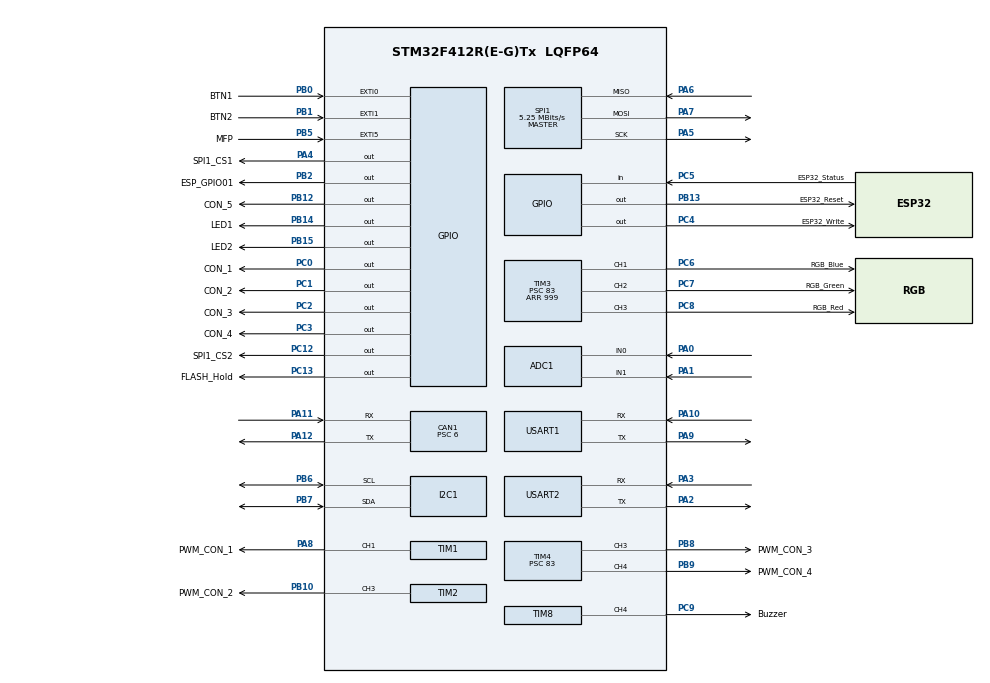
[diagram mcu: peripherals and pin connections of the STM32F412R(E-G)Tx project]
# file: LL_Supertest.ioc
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ADC1.Channel-0\#ChannelRegularConversion=ADC_CHANNEL_0
ADC1.Channel-1\#ChannelRegularConversion=ADC_CHANNEL_1
ADC1.ContinuousConvMode=ENABLE
ADC1.DMAContinuousRequests=ENABLE
ADC1.InjNumberOfConversion=0
ADC1.NbrOfConversion=2
ADC1.NbrOfConversionFlag=1
ADC1.Rank-0\#ChannelRegularConversion=1
ADC1.Rank-1\#ChannelRegularConversion=2
ADC1.SamplingTime-0\#ChannelRegularConversion=ADC_SAMPLETIME_15CYCLES
ADC1.SamplingTime-1\#ChannelRegularConversion=ADC_SAMPLETIME_15CYCLES
ADC1.ScanConvMode=ENABLE
ADC1.master=1
CAN1.BS1=CAN_BS1_11TQ
CAN1.BS2=CAN_BS2_2TQ
CAN1.CalculateBaudRate=500000
CAN1.CalculateTimeBit=2000
CAN1.CalculateTimeQuantum=142.85714285714286
CAN1.NART=ENABLE
CAN1.Prescaler=6
CAN1.SJW=CAN_SJW_1TQ
Dma.ADC1.0.Direction=DMA_PERIPH_TO_MEMORY
Dma.ADC1.0.FIFOMode=DMA_FIFOMODE_DISABLE
Dma.ADC1.0.Instance=DMA2_Stream4
Dma.ADC1.0.MemDataAlignment=DMA_MDATAALIGN_HALFWORD
Dma.ADC1.0.MemInc=DMA_MINC_ENABLE
Dma.ADC1.0.Mode=DMA_CIRCULAR
Dma.ADC1.0.PeriphDataAlignment=DMA_PDATAALIGN_HALFWORD
Dma.ADC1.0.PeriphInc=DMA_PINC_DISABLE
Dma.ADC1.0.Priority=DMA_PRIORITY_LOW
Dma.I2C1_RX.1.Direction=DMA_PERIPH_TO_MEMORY
Dma.I2C1_RX.1.FIFOMode=DMA_FIFOMODE_DISABLE
Dma.I2C1_RX.1.Instance=DMA1_Stream0
Dma.I2C1_RX.1.MemDataAlignment=DMA_MDATAALIGN_BYTE
Dma.I2C1_RX.1.MemInc=DMA_MINC_ENABLE
Dma.I2C1_RX.1.Mode=DMA_NORMAL
Dma.I2C1_RX.1.PeriphDataAlignment=DMA_PDATAALIGN_BYTE
Dma.I2C1_RX.1.PeriphInc=DMA_PINC_DISABLE
Dma.I2C1_RX.1.Priority=DMA_PRIORITY_LOW
Dma.I2C1_TX.2.Direction=DMA_MEMORY_TO_PERIPH
Dma.I2C1_TX.2.FIFOMode=DMA_FIFOMODE_DISABLE
Dma.I2C1_TX.2.Instance=DMA1_Stream1
Dma.I2C1_TX.2.MemDataAlignment=DMA_MDATAALIGN_BYTE
Dma.I2C1_TX.2.MemInc=DMA_MINC_ENABLE
Dma.I2C1_TX.2.Mode=DMA_NORMAL
Dma.I2C1_TX.2.PeriphDataAlignment=DMA_PDATAALIGN_BYTE
Dma.I2C1_TX.2.PeriphInc=DMA_PINC_DISABLE
Dma.I2C1_TX.2.Priority=DMA_PRIORITY_LOW
Dma.Request0=ADC1
Dma.Request1=I2C1_RX
Dma.Request2=I2C1_TX
Dma.Request3=USART1_RX
Dma.Request4=USART1_TX
Dma.Request5=USART2_RX
Dma.Request6=USART2_TX
Dma.Request7=SPI1_RX
Dma.Request8=SPI1_TX
Dma.SPI1_RX.7.Direction=DMA_PERIPH_TO_MEMORY
Dma.SPI1_RX.7.FIFOMode=DMA_FIFOMODE_DISABLE
Dma.SPI1_RX.7.Instance=DMA2_Stream0
Dma.SPI1_RX.7.MemDataAlignment=DMA_MDATAALIGN_BYTE
Dma.SPI1_RX.7.MemInc=DMA_MINC_ENABLE
Dma.SPI1_RX.7.Mode=DMA_NORMAL
Dma.SPI1_RX.7.PeriphDataAlignment=DMA_PDATAALIGN_BYTE
Dma.SPI1_RX.7.PeriphInc=DMA_PINC_DISABLE
Dma.SPI1_RX.7.Priority=DMA_PRIORITY_LOW
Dma.SPI1_TX.8.Direction=DMA_MEMORY_TO_PERIPH
Dma.SPI1_TX.8.FIFOMode=DMA_FIFOMODE_DISABLE
Dma.SPI1_TX.8.Instance=DMA2_Stream3
Dma.SPI1_TX.8.MemDataAlignment=DMA_MDATAALIGN_BYTE
Dma.SPI1_TX.8.MemInc=DMA_MINC_ENABLE
Dma.SPI1_TX.8.Mode=DMA_NORMAL
Dma.SPI1_TX.8.PeriphDataAlignment=DMA_PDATAALIGN_BYTE
Dma.SPI1_TX.8.PeriphInc=DMA_PINC_DISABLE
Dma.SPI1_TX.8.Priority=DMA_PRIORITY_LOW
Dma.USART1_RX.3.Direction=DMA_PERIPH_TO_MEMORY
Dma.USART1_RX.3.FIFOMode=DMA_FIFOMODE_DISABLE
Dma.USART1_RX.3.Instance=DMA2_Stream2
Dma.USART1_RX.3.MemDataAlignment=DMA_MDATAALIGN_BYTE
Dma.USART1_RX.3.MemInc=DMA_MINC_ENABLE
Dma.USART1_RX.3.Mode=DMA_NORMAL
Dma.USART1_RX.3.PeriphDataAlignment=DMA_PDATAALIGN_BYTE
Dma.USART1_RX.3.PeriphInc=DMA_PINC_DISABLE
Dma.USART1_RX.3.Priority=DMA_PRIORITY_LOW
Dma.USART1_TX.4.Direction=DMA_MEMORY_TO_PERIPH
Dma.USART1_TX.4.FIFOMode=DMA_FIFOMODE_DISABLE
Dma.USART1_TX.4.Instance=DMA2_Stream7
Dma.USART1_TX.4.MemDataAlignment=DMA_MDATAALIGN_BYTE
Dma.USART1_TX.4.MemInc=DMA_MINC_ENABLE
Dma.USART1_TX.4.Mode=DMA_NORMAL
Dma.USART1_TX.4.PeriphDataAlignment=DMA_PDATAALIGN_BYTE
Dma.USART1_TX.4.PeriphInc=DMA_PINC_DISABLE
Dma.USART1_TX.4.Priority=DMA_PRIORITY_LOW
Dma.USART2_RX.5.Direction=DMA_PERIPH_TO_MEMORY
Dma.USART2_RX.5.FIFOMode=DMA_FIFOMODE_DISABLE
Dma.USART2_RX.5.Instance=DMA1_Stream5
Dma.USART2_RX.5.MemDataAlignment=DMA_MDATAALIGN_BYTE
Dma.USART2_RX.5.MemInc=DMA_MINC_ENABLE
Dma.USART2_RX.5.Mode=DMA_NORMAL
Dma.USART2_RX.5.PeriphDataAlignment=DMA_PDATAALIGN_BYTE
Dma.USART2_RX.5.PeriphInc=DMA_PINC_DISABLE
Dma.USART2_RX.5.Priority=DMA_PRIORITY_LOW
Dma.USART2_TX.6.Direction=DMA_MEMORY_TO_PERIPH
Dma.USART2_TX.6.FIFOMode=DMA_FIFOMODE_DISABLE
Dma.USART2_TX.6.Instance=DMA1_Stream6
Dma.USART2_TX.6.MemDataAlignment=DMA_MDATAALIGN_BYTE
Dma.USART2_TX.6.MemInc=DMA_MINC_ENABLE
Dma.USART2_TX.6.Mode=DMA_NORMAL
Dma.USART2_TX.6.PeriphDataAlignment=DMA_PDATAALIGN_BYTE
Dma.USART2_TX.6.PeriphInc=DMA_PINC_DISABLE
Dma.USART2_TX.6.Priority=DMA_PRIORITY_LOW
Mcu.Family=STM32F4
Mcu.Name=STM32F412R(E-G)Tx
Mcu.Package=LQFP64
Mcu.UserConstants=ADC_CHANNEL_COUNT,2;ADC_SAMPLES_PER_CHANNEL,1;ADC_BUFFER_SIZE,(ADC_CHANNEL_COUNT * ADC_SAMPLES_PER_CHANNEL);FRAME_LEN_APP,32;FRAME_HEADER_SIZE,5;FRAME_PAYLOAD_SIZE,(FRAME_LEN_APP - FRAME_HEADER_SIZE);UART1_RX_BUFFER_SIZE,128;UART1_RX_FRAME_LEN,FRAME_LEN_APP;UART2_RX_BUFFER_SIZE,128;UART2_RX_FRAME_LEN,FRAME_LEN_APP
NVIC.CAN1_RX0_IRQn=true\:0\:0\:false\:false\:true\:true\:true\:true
NVIC.CAN1_RX1_IRQn=true\:0\:0\:false\:false\:true\:true\:true\:true
NVIC.CAN1_SCE_IRQn=true\:0\:0\:false\:false\:true\:true\:true\:true
NVIC.CAN1_TX_IRQn=true\:0\:0\:false\:false\:true\:true\:true\:true
NVIC.DMA1_Stream0_IRQn=true\:0\:0\:false\:false\:true\:false\:true\:true
NVIC.DMA1_Stream1_IRQn=true\:0\:0\:false\:false\:true\:false\:true\:true
NVIC.DMA1_Stream5_IRQn=true\:0\:0\:false\:false\:true\:false\:true\:true
NVIC.DMA1_Stream6_IRQn=true\:0\:0\:false\:false\:true\:false\:true\:true
NVIC.DMA2_Stream0_IRQn=true\:0\:0\:false\:false\:true\:false\:true\:true
NVIC.DMA2_Stream2_IRQn=true\:0\:0\:false\:false\:true\:false\:true\:true
NVIC.DMA2_Stream3_IRQn=true\:0\:0\:false\:false\:true\:false\:true\:true
NVIC.DMA2_Stream4_IRQn=true\:0\:0\:false\:false\:true\:false\:true\:true
NVIC.DMA2_Stream7_IRQn=true\:0\:0\:false\:false\:true\:false\:true\:true
NVIC.I2C1_ER_IRQn=true\:0\:0\:false\:false\:true\:true\:true\:true
NVIC.I2C1_EV_IRQn=true\:0\:0\:false\:false\:true\:true\:true\:true
NVIC.PriorityGroup=NVIC_PRIORITYGROUP_4
NVIC.SPI1_IRQn=true\:0\:0\:false\:false\:true\:true\:true\:true
NVIC.TIM8_UP_TIM13_IRQn=true\:0\:0\:false\:false\:true\:true\:true\:true
NVIC.USART1_IRQn=true\:0\:0\:false\:false\:true\:false\:true\:true
NVIC.USART2_IRQn=true\:0\:0\:false\:false\:true\:false\:true\:true
PA0.Signal=ADCx_IN0
PA1.Signal=ADCx_IN1
PA10.Mode=Asynchronous
PA10.Signal=USART1_RX
PA11.Mode=CAN_Activate
PA11.Signal=CAN1_RX
PA12.Mode=CAN_Activate
PA12.Signal=CAN1_TX
PA13.Mode=JTAG_4_pins
PA13.Signal=SYS_JTMS-SWDIO
PA14.Mode=JTAG_4_pins
PA14.Signal=SYS_JTCK-SWCLK
PA15.Mode=JTAG_4_pins
PA15.Signal=SYS_JTDI
PA2.Mode=Asynchronous
PA2.Signal=USART2_TX
PA3.Mode=Asynchronous
PA3.Signal=USART2_RX
PA4.GPIO_Label=SPI1_CS1
PA4.Signal=GPIO_Output
PA5.Mode=Full_Duplex_Master
PA5.Signal=SPI1_SCK
PA6.Mode=Full_Duplex_Master
PA6.Signal=SPI1_MISO
PA7.Mode=Full_Duplex_Master
PA7.Signal=SPI1_MOSI
PA8.GPIO_Label=PWM_CON_1
PA8.Signal=S_TIM1_CH1
PA9.Mode=Asynchronous
PA9.Signal=USART1_TX
PB0.GPIO_Label=BTN1
PB0.GPIO_ModeDefaultEXTI=GPIO_MODE_IT_FALLING
PB0.GPIO_PuPd=GPIO_PULLUP
PB0.Signal=GPXTI0
PB1.GPIO_Label=BTN2
PB1.GPIO_ModeDefaultEXTI=GPIO_MODE_IT_FALLING
PB1.GPIO_PuPd=GPIO_PULLUP
PB1.Signal=GPXTI1
PB10.GPIO_Label=PWM_CON_2
PB10.Signal=S_TIM2_CH3
PB12.GPIO_Label=CON_5
PB12.Signal=GPIO_Output
PB13.GPIO_Label=ESP32_Reset
PB13.Signal=GPIO_Output
PB14.GPIO_Label=LED1
PB14.Signal=GPIO_Output
PB15.GPIO_Label=LED2
PB15.Signal=GPIO_Output
PB2.GPIO_Label=ESP_GPIO01
PB2.Signal=GPIO_Output
PB3.Mode=JTAG_4_pins
PB3.Signal=SYS_JTDO-SWO
PB5.GPIO_Label=MFP
PB5.GPIO_ModeDefaultEXTI=GPIO_MODE_IT_FALLING
PB5.Signal=GPXTI5
PB6.Mode=I2C
PB6.Signal=I2C1_SCL
PB7.Mode=I2C
PB7.Signal=I2C1_SDA
PB8.GPIO_Label=PWM_CON_3
PB8.Signal=S_TIM4_CH3
PB9.GPIO_Label=PWM_CON_4
PB9.Signal=S_TIM4_CH4
PC0.GPIO_Label=CON_1
PC0.Signal=GPIO_Output
PC1.GPIO_Label=CON_2
PC1.Signal=GPIO_Output
PC12.GPIO_Label=SPI1_CS2
PC12.Signal=GPIO_Output
PC13.GPIO_Label=FLASH_Hold
PC13.Signal=GPIO_Output
PC14-OSC32_IN.Mode=LSE-External-Oscillator
PC14-OSC32_IN.Signal=RCC_OSC32_IN
PC15-OSC32_OUT.Mode=LSE-External-Oscillator
PC15-OSC32_OUT.Signal=RCC_OSC32_OUT
PC2.GPIO_Label=CON_3
PC2.Signal=GPIO_Output
PC3.GPIO_Label=CON_4
PC3.Signal=GPIO_Output
PC4.GPIO_Label=ESP32_Write
PC4.Signal=GPIO_Output
PC5.GPIO_Label=ESP32_Status
PC5.Signal=GPIO_Input
PC6.GPIO_Label=RGB_Blue
PC6.Signal=S_TIM3_CH1
PC7.GPIO_Label=RGB_Green
PC7.Signal=S_TIM3_CH2
PC8.GPIO_Label=RGB_Red
PC8.Signal=S_TIM3_CH3
PC9.GPIO_Label=Buzzer
PC9.Signal=S_TIM8_CH4
PH0\ -\ OSC_IN.Mode=HSE-External-Clock-Source
PH0\ -\ OSC_IN.Signal=RCC_OSC_IN
PH1\ -\ OSC_OUT.Mode=HSE-External-Clock-Source
PH1\ -\ OSC_OUT.Signal=RCC_OSC_OUT
ProjectManager.HeapSize=0x200
ProjectManager.StackSize=0x400
ProjectManager.TargetToolchain=CMake
RCC.AHBFreq_Value=84000000
RCC.APB1CLKDivider=RCC_HCLK_DIV2
RCC.APB1Freq_Value=42000000
RCC.APB1TimFreq_Value=84000000
RCC.APB2Freq_Value=84000000
RCC.APB2TimFreq_Value=84000000
RCC.CortexFreq_Value=84000000
RCC.HCLKFreq_Value=84000000
RCC.PLLM=8
RCC.PLLN=84
RCC.SYSCLKFreq_VALUE=84000000
RCC.SYSCLKSource=RCC_SYSCLKSOURCE_PLLCLK
RCC.USBFreq_Value=84000000
RCC.VCOOutputFreq_Value=168000000
SH.ADCx_IN0.0=ADC1_IN0,IN0
SH.ADCx_IN1.0=ADC1_IN1,IN1
SH.S_TIM1_CH1.0=TIM1_CH1,PWM Generation1 CH1
SH.S_TIM2_CH3.0=TIM2_CH3,PWM Generation3 CH3
SH.S_TIM3_CH1.0=TIM3_CH1,PWM Generation1 CH1
SH.S_TIM3_CH2.0=TIM3_CH2,PWM Generation2 CH2
SH.S_TIM3_CH3.0=TIM3_CH3,PWM Generation3 CH3
SH.S_TIM4_CH3.0=TIM4_CH3,PWM Generation3 CH3
SH.S_TIM4_CH4.0=TIM4_CH4,PWM Generation4 CH4
SH.S_TIM8_CH4.0=TIM8_CH4,PWM Generation4 CH4
SPI1.BaudRatePrescaler=SPI_BAUDRATEPRESCALER_16
SPI1.CRCCalculation=SPI_CRCCALCULATION_DISABLE
SPI1.CalculateBaudRate=5.25 MBits/s
SPI1.Direction=SPI_DIRECTION_2LINES
SPI1.Mode=SPI_MODE_MASTER
SPI1.VirtualType=VM_MASTER
TIM1.Channel-PWM\ Generation1\ CH1=TIM_CHANNEL_1
TIM1.Period=999
TIM1.Prescaler=83
TIM13.Channel=TIM_CHANNEL_1
TIM13.Period=999
TIM13.Prescaler=83
TIM13.Pulse=500
TIM2.Channel-PWM\ Generation3\ CH3=TIM_CHANNEL_3
TIM2.Period=999
TIM2.Prescaler=83
TIM3.Channel-PWM\ Generation1\ CH1=TIM_CHANNEL_1
TIM3.Channel-PWM\ Generation2\ CH2=TIM_CHANNEL_2
TIM3.Channel-PWM\ Generation3\ CH3=TIM_CHANNEL_3
TIM3.Period=999
TIM3.Prescaler=83
TIM4.Channel-PWM\ Generation3\ CH3=TIM_CHANNEL_3
TIM4.Channel-PWM\ Generation4\ CH4=TIM_CHANNEL_4
TIM4.Period=999
TIM4.Prescaler=83
TIM8.Channel-PWM\ Generation4\ CH4=TIM_CHANNEL_4
TIM8.Period=999
TIM8.Prescaler=83
USART1.VirtualMode=VM_ASYNC
USART2.VirtualMode=VM_ASYNC
VP_CRC_VS_CRC.Mode=CRC_Activate
VP_RTC_VS_RTC_Activate.Mode=RTC_Enabled
VP_RTC_VS_RTC_Calendar.Mode=RTC_Calendar
VP_TIM13_VS_ClockSourceINT.Mode=Enable_Timer
VP_TIM13_VS_no_output1.Mode=Output Compare1 No Output
board=custom

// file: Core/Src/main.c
#include "main.h"
#include "app_flags.h"
#include "support.h"
#include "uart_protocol.h"
#include "uart.h"
#include "spi.h"
#include "bme280.h"
#include "sht40.h"
#include "lcd.h"
#include "rtc.h"
#include "can.h"
#include "can_protocol.h"

CAN_HandleTypeDef hcan1;

void SystemClock_Config(void);
static void MX_GPIO_Init(void);
static void MX_DMA_Init(void);
static void MX_ADC1_Init(void);
static void MX_CAN1_Init(void);
static void MX_I2C1_Init(void);
static void MX_TIM1_Init(void);
static void MX_TIM2_Init(void);
static void MX_TIM3_Init(void);
static void MX_TIM4_Init(void);
static void MX_TIM8_Init(void);
static void MX_TIM13_Init(void);
static void MX_USART1_UART_Init(void);
static void MX_USART2_UART_Init(void);
static void MX_SPI1_Init(void);
static void MX_CRC_Init(void);
static void MX_RTC_Init(void);

int main(void)
{

  /* MCU Configuration--------------------------------------------------------*/

  /* Reset of all peripherals, Initializes the Flash interface and the Systick. */
  __disable_irq();
  SCB->VTOR = 0x08008000U;
  __DSB(); __ISB();

  HAL_Init();

  /* Configure the system clock */
  SystemClock_Config();

  /* Initialize all configured peripherals */
  MX_GPIO_Init();
  MX_DMA_Init();
  MX_ADC1_Init();
  MX_CAN1_Init();
  MX_I2C1_Init();
  MX_TIM1_Init();
  MX_TIM2_Init();
  MX_TIM3_Init();
  MX_TIM4_Init();
  MX_TIM8_Init();
  MX_TIM13_Init();
  MX_USART1_UART_Init();
  MX_USART2_UART_Init();
  MX_SPI1_Init();
  MX_CRC_Init();
  MX_RTC_Init();

  dma1_uart2_rx_config(uart2_rx_buf, UART2_RX_BUFFER_SIZE);
  dma2_uart1_rx_config(uart1_rx_buf, UART1_RX_BUFFER_SIZE);

  __enable_irq();

  bme280_init();

  lcd_init();
  lcd_set_cursor(0, 0);
  lcd_send_string("Initializing...");

  if (can_start() != 0)
  {
      Error_Handler();
  }

  /* Infinite loop */
  /* USER CODE BEGIN WHILE */

  while (1)
  {

    uart2_process_rx();
    uart1_process_rx();

    if (btn1_flag)
    {
      btn1_flag = 0;
      LL_GPIO_TogglePin(LED1_GPIO_Port, LED1_Pin);
    }

    if (btn2_flag)
    {
      btn2_flag = 0;
      LL_GPIO_TogglePin(LED2_GPIO_Port, LED2_Pin);
    }

    bme280_task();
    sht40_task();

    if (flag_100ms)
    {
      flag_100ms = 0;
      send_cyclic_frames();
    }

    if (flag_1s)
    {
      flag_1s = 0;
      LL_GPIO_TogglePin(LED1_GPIO_Port, LED1_Pin);

      rtc_get_datetime(&datetime.year, &datetime.month, &datetime.day, &datetime.weekday, &datetime.hours, &datetime.minutes, &datetime.seconds);
    }
    /* USER CODE END WHILE */

  }
}

void SystemClock_Config(void)
{
  LL_FLASH_SetLatency(LL_FLASH_LATENCY_2);
  while(LL_FLASH_GetLatency()!= LL_FLASH_LATENCY_2)
  {
  }
  LL_PWR_SetRegulVoltageScaling(LL_PWR_REGU_VOLTAGE_SCALE1);
  LL_RCC_HSI_SetCalibTrimming(16);
  LL_RCC_HSI_Enable();

   /* Wait till HSI is ready */
  while(LL_RCC_HSI_IsReady() != 1)
  {

  }
  LL_RCC_LSI_Enable();

   /* Wait till LSI is ready */
  while(LL_RCC_LSI_IsReady() != 1)
  {

  }
  LL_PWR_EnableBkUpAccess();
  LL_RCC_PLL_ConfigDomain_SYS(LL_RCC_PLLSOURCE_HSI, LL_RCC_PLLM_DIV_8, 84, LL_RCC_PLLP_DIV_2);
  LL_RCC_PLL_Enable();

   /* Wait till PLL is ready */
  while(LL_RCC_PLL_IsReady() != 1)
  {

  }
  while (LL_PWR_IsActiveFlag_VOS() == 0)
  {
  }
  LL_RCC_SetAHBPrescaler(LL_RCC_SYSCLK_DIV_1);
  LL_RCC_SetAPB1Prescaler(LL_RCC_APB1_DIV_2);
  LL_RCC_SetAPB2Prescaler(LL_RCC_APB2_DIV_1);
  LL_RCC_SetSysClkSource(LL_RCC_SYS_CLKSOURCE_PLL);

   /* Wait till System clock is ready */
  while(LL_RCC_GetSysClkSource() != LL_RCC_SYS_CLKSOURCE_STATUS_PLL)
  {

  }
  LL_SetSystemCoreClock(84000000);

   /* Update the time base */
  if (HAL_InitTick (TICK_INT_PRIORITY) != HAL_OK)
  {
    Error_Handler();
  }
  LL_RCC_SetTIMPrescaler(LL_RCC_TIM_PRESCALER_TWICE);
}

static void MX_ADC1_Init(void)
{

  LL_ADC_InitTypeDef ADC_InitStruct = {0};
  LL_ADC_REG_InitTypeDef ADC_REG_InitStruct = {0};
  LL_ADC_CommonInitTypeDef ADC_CommonInitStruct = {0};

  LL_GPIO_InitTypeDef GPIO_InitStruct = {0};

  /* Peripheral clock enable */
  LL_APB2_GRP1_EnableClock(LL_APB2_GRP1_PERIPH_ADC1);

  LL_AHB1_GRP1_EnableClock(LL_AHB1_GRP1_PERIPH_GPIOA);
  /**ADC1 GPIO Configuration
  PA0   ------> ADC1_IN0
  PA1   ------> ADC1_IN1
  */
  GPIO_InitStruct.Pin = LL_GPIO_PIN_0|LL_GPIO_PIN_1;
  GPIO_InitStruct.Mode = LL_GPIO_MODE_ANALOG;
  GPIO_InitStruct.Pull = LL_GPIO_PULL_NO;
  LL_GPIO_Init(GPIOA, &GPIO_InitStruct);

  /* ADC1 DMA Init */

  /* ADC1 Init */
  LL_DMA_SetChannelSelection(DMA2, LL_DMA_STREAM_4, LL_DMA_CHANNEL_0);

  LL_DMA_SetDataTransferDirection(DMA2, LL_DMA_STREAM_4, LL_DMA_DIRECTION_PERIPH_TO_MEMORY);

  LL_DMA_SetStreamPriorityLevel(DMA2, LL_DMA_STREAM_4, LL_DMA_PRIORITY_LOW);

  LL_DMA_SetMode(DMA2, LL_DMA_STREAM_4, LL_DMA_MODE_CIRCULAR);

  LL_DMA_SetPeriphIncMode(DMA2, LL_DMA_STREAM_4, LL_DMA_PERIPH_NOINCREMENT);

  LL_DMA_SetMemoryIncMode(DMA2, LL_DMA_STREAM_4, LL_DMA_MEMORY_INCREMENT);

  LL_DMA_SetPeriphSize(DMA2, LL_DMA_STREAM_4, LL_DMA_PDATAALIGN_HALFWORD);

  LL_DMA_SetMemorySize(DMA2, LL_DMA_STREAM_4, LL_DMA_MDATAALIGN_HALFWORD);

  LL_DMA_DisableFifoMode(DMA2, LL_DMA_STREAM_4);

  /** Common config
  */
  ADC_InitStruct.Resolution = LL_ADC_RESOLUTION_12B;
  ADC_InitStruct.DataAlignment = LL_ADC_DATA_ALIGN_RIGHT;
  ADC_InitStruct.SequencersScanMode = LL_ADC_SEQ_SCAN_ENABLE;
  LL_ADC_Init(ADC1, &ADC_InitStruct);
  ADC_REG_InitStruct.TriggerSource = LL_ADC_REG_TRIG_SOFTWARE;
  ADC_REG_InitStruct.SequencerLength = LL_ADC_REG_SEQ_SCAN_ENABLE_2RANKS;
  ADC_REG_InitStruct.SequencerDiscont = LL_ADC_REG_SEQ_DISCONT_DISABLE;
  ADC_REG_InitStruct.ContinuousMode = LL_ADC_REG_CONV_CONTINUOUS;
  ADC_REG_InitStruct.DMATransfer = LL_ADC_REG_DMA_TRANSFER_UNLIMITED;
  LL_ADC_REG_Init(ADC1, &ADC_REG_InitStruct);
  LL_ADC_REG_SetFlagEndOfConversion(ADC1, LL_ADC_REG_FLAG_EOC_UNITARY_CONV);
  ADC_CommonInitStruct.CommonClock = LL_ADC_CLOCK_SYNC_PCLK_DIV4;
  LL_ADC_CommonInit(__LL_ADC_COMMON_INSTANCE(ADC1), &ADC_CommonInitStruct);

  /** Configure Regular Channel
  */
  LL_ADC_REG_SetSequencerRanks(ADC1, LL_ADC_REG_RANK_1, LL_ADC_CHANNEL_0);
  LL_ADC_SetChannelSamplingTime(ADC1, LL_ADC_CHANNEL_0, LL_ADC_SAMPLINGTIME_15CYCLES);

  /** Configure Regular Channel
  */
  LL_ADC_REG_SetSequencerRanks(ADC1, LL_ADC_REG_RANK_2, LL_ADC_CHANNEL_1);
  LL_ADC_SetChannelSamplingTime(ADC1, LL_ADC_CHANNEL_1, LL_ADC_SAMPLINGTIME_15CYCLES);

  LL_DMA_SetPeriphAddress(DMA2, LL_DMA_STREAM_4, LL_ADC_DMA_GetRegAddr(ADC1, LL_ADC_DMA_REG_REGULAR_DATA));
  LL_DMA_SetMemoryAddress(DMA2, LL_DMA_STREAM_4, (uint32_t)adc_data_buffer);
  LL_DMA_SetDataLength(DMA2, LL_DMA_STREAM_4, ADC_BUFFER_SIZE);
  LL_DMA_EnableIT_TC(DMA2, LL_DMA_STREAM_4);
  LL_DMA_EnableIT_TE(DMA2, LL_DMA_STREAM_4);
  LL_DMA_EnableStream(DMA2, LL_DMA_STREAM_4);
  LL_ADC_Enable(ADC1);
  LL_ADC_REG_StartConversionSWStart(ADC1);
  adc_present = 1;

}

static void MX_CAN1_Init(void)
{
    hcan1.Instance = CAN1;
    hcan1.Init.Prescaler = 6;
    hcan1.Init.Mode = CAN_MODE_NORMAL;
    hcan1.Init.SyncJumpWidth = CAN_SJW_1TQ;
    hcan1.Init.TimeSeg1 = CAN_BS1_11TQ;
    hcan1.Init.TimeSeg2 = CAN_BS2_2TQ;
    hcan1.Init.TimeTriggeredMode = DISABLE;
    hcan1.Init.AutoBusOff = ENABLE;
    hcan1.Init.AutoWakeUp = DISABLE;
    hcan1.Init.AutoRetransmission = DISABLE;
    hcan1.Init.ReceiveFifoLocked = DISABLE;
    hcan1.Init.TransmitFifoPriority = ENABLE;

    if (HAL_CAN_Init(&hcan1) != HAL_OK)
    {
        Error_Handler();
    }
}

static void MX_CRC_Init(void)
{

  /* Peripheral clock enable */
  LL_AHB1_GRP1_EnableClock(LL_AHB1_GRP1_PERIPH_CRC);

}

static void MX_I2C1_Init(void)
{

  LL_I2C_InitTypeDef I2C_InitStruct = {0};

  LL_GPIO_InitTypeDef GPIO_InitStruct = {0};

  LL_AHB1_GRP1_EnableClock(LL_AHB1_GRP1_PERIPH_GPIOB);
  /**I2C1 GPIO Configuration
  PB6   ------> I2C1_SCL
  PB7   ------> I2C1_SDA
  */
  GPIO_InitStruct.Pin = LL_GPIO_PIN_6|LL_GPIO_PIN_7;
  GPIO_InitStruct.Mode = LL_GPIO_MODE_ALTERNATE;
  GPIO_InitStruct.Speed = LL_GPIO_SPEED_FREQ_VERY_HIGH;
  GPIO_InitStruct.OutputType = LL_GPIO_OUTPUT_OPENDRAIN;
  GPIO_InitStruct.Pull = LL_GPIO_PULL_NO;
  GPIO_InitStruct.Alternate = LL_GPIO_AF_4;
  LL_GPIO_Init(GPIOB, &GPIO_InitStruct);

  /* Peripheral clock enable */
  LL_APB1_GRP1_EnableClock(LL_APB1_GRP1_PERIPH_I2C1);

  /* I2C1 DMA Init */

  /* I2C1_RX Init */
  LL_DMA_SetChannelSelection(DMA1, LL_DMA_STREAM_0, LL_DMA_CHANNEL_1);

  LL_DMA_SetDataTransferDirection(DMA1, LL_DMA_STREAM_0, LL_DMA_DIRECTION_PERIPH_TO_MEMORY);

  LL_DMA_SetStreamPriorityLevel(DMA1, LL_DMA_STREAM_0, LL_DMA_PRIORITY_LOW);

  LL_DMA_SetMode(DMA1, LL_DMA_STREAM_0, LL_DMA_MODE_NORMAL);

  LL_DMA_SetPeriphIncMode(DMA1, LL_DMA_STREAM_0, LL_DMA_PERIPH_NOINCREMENT);

  LL_DMA_SetMemoryIncMode(DMA1, LL_DMA_STREAM_0, LL_DMA_MEMORY_INCREMENT);

  LL_DMA_SetPeriphSize(DMA1, LL_DMA_STREAM_0, LL_DMA_PDATAALIGN_BYTE);

  LL_DMA_SetMemorySize(DMA1, LL_DMA_STREAM_0, LL_DMA_MDATAALIGN_BYTE);

  LL_DMA_DisableFifoMode(DMA1, LL_DMA_STREAM_0);

  /* I2C1_TX Init */
  LL_DMA_SetChannelSelection(DMA1, LL_DMA_STREAM_1, LL_DMA_CHANNEL_0);

  LL_DMA_SetDataTransferDirection(DMA1, LL_DMA_STREAM_1, LL_DMA_DIRECTION_MEMORY_TO_PERIPH);

  LL_DMA_SetStreamPriorityLevel(DMA1, LL_DMA_STREAM_1, LL_DMA_PRIORITY_LOW);

  LL_DMA_SetMode(DMA1, LL_DMA_STREAM_1, LL_DMA_MODE_NORMAL);

  LL_DMA_SetPeriphIncMode(DMA1, LL_DMA_STREAM_1, LL_DMA_PERIPH_NOINCREMENT);

  LL_DMA_SetMemoryIncMode(DMA1, LL_DMA_STREAM_1, LL_DMA_MEMORY_INCREMENT);

  LL_DMA_SetPeriphSize(DMA1, LL_DMA_STREAM_1, LL_DMA_PDATAALIGN_BYTE);

  LL_DMA_SetMemorySize(DMA1, LL_DMA_STREAM_1, LL_DMA_MDATAALIGN_BYTE);

  LL_DMA_DisableFifoMode(DMA1, LL_DMA_STREAM_1);

  /** I2C Initialization
  */
  LL_I2C_DisableOwnAddress2(I2C1);
  LL_I2C_DisableGeneralCall(I2C1);
  LL_I2C_EnableClockStretching(I2C1);
  I2C_InitStruct.PeripheralMode = LL_I2C_MODE_I2C;
  I2C_InitStruct.ClockSpeed = 100000;
  I2C_InitStruct.DutyCycle = LL_I2C_DUTYCYCLE_2;
  I2C_InitStruct.OwnAddress1 = 0;
  I2C_InitStruct.TypeAcknowledge = LL_I2C_ACK;
  I2C_InitStruct.OwnAddrSize = LL_I2C_OWNADDRESS1_7BIT;
  LL_I2C_Init(I2C1, &I2C_InitStruct);
  LL_I2C_SetOwnAddress2(I2C1, 0);
  LL_I2C_EnableDMAReq_RX(I2C1);
  LL_I2C_EnableDMAReq_TX(I2C1);
  LL_I2C_Enable(I2C1);
}

static void MX_RTC_Init(void)
{

  LL_RTC_InitTypeDef RTC_InitStruct = {0};
  LL_RTC_TimeTypeDef RTC_TimeStruct = {0};
  LL_RTC_DateTypeDef RTC_DateStruct = {0};

  if(LL_RCC_GetRTCClockSource() != LL_RCC_RTC_CLKSOURCE_LSI)
  {
    LL_RCC_ForceBackupDomainReset();
    LL_RCC_ReleaseBackupDomainReset();
  LL_RCC_SetRTCClockSource(LL_RCC_RTC_CLKSOURCE_LSI);
  }

  /* Peripheral clock enable */
  LL_RCC_EnableRTC();

  /** Initialize RTC and set the Time and Date
  */
  RTC_InitStruct.HourFormat = LL_RTC_HOURFORMAT_24HOUR;
  RTC_InitStruct.AsynchPrescaler = 127;
  RTC_InitStruct.SynchPrescaler = 255;
  LL_RTC_Init(RTC, &RTC_InitStruct);
  LL_RTC_SetAsynchPrescaler(RTC, 127);
  LL_RTC_SetSynchPrescaler(RTC, 255);

  /** Initialize RTC and set the Time and Date
  */
  if(LL_RTC_BAK_GetRegister(RTC, LL_RTC_BKP_DR0) != 0x32F2){

  RTC_TimeStruct.Hours = 0;
  RTC_TimeStruct.Minutes = 0;
  RTC_TimeStruct.Seconds = 0;
  LL_RTC_TIME_Init(RTC, LL_RTC_FORMAT_BCD, &RTC_TimeStruct);
  RTC_DateStruct.WeekDay = LL_RTC_WEEKDAY_MONDAY;
  RTC_DateStruct.Month = LL_RTC_MONTH_JANUARY;
  RTC_DateStruct.Day = 0x1;
  RTC_DateStruct.Year = 0;
  LL_RTC_DATE_Init(RTC, LL_RTC_FORMAT_BCD, &RTC_DateStruct);
    LL_RTC_BAK_SetRegister(RTC,LL_RTC_BKP_DR0,0x32F2);
  }

}

static void MX_SPI1_Init(void)
{
  LL_SPI_InitTypeDef SPI_InitStruct = {0};

  LL_GPIO_InitTypeDef GPIO_InitStruct = {0};

  LL_APB2_GRP1_EnableClock(LL_APB2_GRP1_PERIPH_SPI1);

  LL_AHB1_GRP1_EnableClock(LL_AHB1_GRP1_PERIPH_GPIOA);

  GPIO_InitStruct.Pin = LL_GPIO_PIN_5|LL_GPIO_PIN_6|LL_GPIO_PIN_7;
  GPIO_InitStruct.Mode = LL_GPIO_MODE_ALTERNATE;
  GPIO_InitStruct.Speed = LL_GPIO_SPEED_FREQ_VERY_HIGH;
  GPIO_InitStruct.OutputType = LL_GPIO_OUTPUT_PUSHPULL;
  GPIO_InitStruct.Pull = LL_GPIO_PULL_NO;
  GPIO_InitStruct.Alternate = LL_GPIO_AF_5;
  LL_GPIO_Init(GPIOA, &GPIO_InitStruct);

  /* SPI1 DMA Init */

  /* SPI1_RX Init */
  LL_DMA_SetChannelSelection(DMA2, LL_DMA_STREAM_0, LL_DMA_CHANNEL_3);

  LL_DMA_SetDataTransferDirection(DMA2, LL_DMA_STREAM_0, LL_DMA_DIRECTION_PERIPH_TO_MEMORY);

  LL_DMA_SetStreamPriorityLevel(DMA2, LL_DMA_STREAM_0, LL_DMA_PRIORITY_LOW);

  LL_DMA_SetMode(DMA2, LL_DMA_STREAM_0, LL_DMA_MODE_NORMAL);

  LL_DMA_SetPeriphIncMode(DMA2, LL_DMA_STREAM_0, LL_DMA_PERIPH_NOINCREMENT);

  LL_DMA_SetMemoryIncMode(DMA2, LL_DMA_STREAM_0, LL_DMA_MEMORY_INCREMENT);

  LL_DMA_SetPeriphSize(DMA2, LL_DMA_STREAM_0, LL_DMA_PDATAALIGN_BYTE);

  LL_DMA_SetMemorySize(DMA2, LL_DMA_STREAM_0, LL_DMA_MDATAALIGN_BYTE);

  LL_DMA_DisableFifoMode(DMA2, LL_DMA_STREAM_0);

  /* SPI1_TX Init */
  LL_DMA_SetChannelSelection(DMA2, LL_DMA_STREAM_3, LL_DMA_CHANNEL_3);

  LL_DMA_SetDataTransferDirection(DMA2, LL_DMA_STREAM_3, LL_DMA_DIRECTION_MEMORY_TO_PERIPH);

  LL_DMA_SetStreamPriorityLevel(DMA2, LL_DMA_STREAM_3, LL_DMA_PRIORITY_LOW);

  LL_DMA_SetMode(DMA2, LL_DMA_STREAM_3, LL_DMA_MODE_NORMAL);

  LL_DMA_SetPeriphIncMode(DMA2, LL_DMA_STREAM_3, LL_DMA_PERIPH_NOINCREMENT);

  LL_DMA_SetMemoryIncMode(DMA2, LL_DMA_STREAM_3, LL_DMA_MEMORY_INCREMENT);

  LL_DMA_SetPeriphSize(DMA2, LL_DMA_STREAM_3, LL_DMA_PDATAALIGN_BYTE);

  LL_DMA_SetMemorySize(DMA2, LL_DMA_STREAM_3, LL_DMA_MDATAALIGN_BYTE);

  LL_DMA_DisableFifoMode(DMA2, LL_DMA_STREAM_3);

  /* SPI1 parameter configuration*/
  SPI_InitStruct.TransferDirection = LL_SPI_FULL_DUPLEX;
  SPI_InitStruct.Mode = LL_SPI_MODE_MASTER;
  SPI_InitStruct.DataWidth = LL_SPI_DATAWIDTH_8BIT;
  SPI_InitStruct.ClockPolarity = LL_SPI_POLARITY_LOW;
  SPI_InitStruct.ClockPhase = LL_SPI_PHASE_1EDGE;
  SPI_InitStruct.NSS = LL_SPI_NSS_SOFT;
  SPI_InitStruct.BaudRate = LL_SPI_BAUDRATEPRESCALER_DIV16;
  SPI_InitStruct.BitOrder = LL_SPI_MSB_FIRST;
  SPI_InitStruct.CRCCalculation = LL_SPI_CRCCALCULATION_DISABLE;
  SPI_InitStruct.CRCPoly = 10;
  LL_SPI_Init(SPI1, &SPI_InitStruct);
  LL_SPI_SetStandard(SPI1, LL_SPI_PROTOCOL_MOTOROLA);
  LL_SPI_EnableDMAReq_RX(SPI1);
  LL_SPI_EnableDMAReq_TX(SPI1);
  LL_SPI_Enable(SPI1);
}

static void MX_TIM1_Init(void)
{

  LL_TIM_InitTypeDef TIM_InitStruct = {0};
  LL_TIM_OC_InitTypeDef TIM_OC_InitStruct = {0};
  LL_TIM_BDTR_InitTypeDef TIM_BDTRInitStruct = {0};

  LL_GPIO_InitTypeDef GPIO_InitStruct = {0};

  /* Peripheral clock enable */
  LL_APB2_GRP1_EnableClock(LL_APB2_GRP1_PERIPH_TIM1);

  TIM_InitStruct.Prescaler = 83;
  TIM_InitStruct.CounterMode = LL_TIM_COUNTERMODE_UP;
  TIM_InitStruct.Autoreload = 999;
  TIM_InitStruct.ClockDivision = LL_TIM_CLOCKDIVISION_DIV1;
  TIM_InitStruct.RepetitionCounter = 0;
  LL_TIM_Init(TIM1, &TIM_InitStruct);
  LL_TIM_DisableARRPreload(TIM1);
  LL_TIM_OC_EnablePreload(TIM1, LL_TIM_CHANNEL_CH1);
  TIM_OC_InitStruct.OCMode = LL_TIM_OCMODE_PWM1;
  TIM_OC_InitStruct.OCState = LL_TIM_OCSTATE_DISABLE;
  TIM_OC_InitStruct.OCNState = LL_TIM_OCSTATE_DISABLE;
  TIM_OC_InitStruct.CompareValue = 0;
  TIM_OC_InitStruct.OCPolarity = LL_TIM_OCPOLARITY_HIGH;
  TIM_OC_InitStruct.OCNPolarity = LL_TIM_OCPOLARITY_HIGH;
  TIM_OC_InitStruct.OCIdleState = LL_TIM_OCIDLESTATE_LOW;
  TIM_OC_InitStruct.OCNIdleState = LL_TIM_OCIDLESTATE_LOW;
  LL_TIM_OC_Init(TIM1, LL_TIM_CHANNEL_CH1, &TIM_OC_InitStruct);
  LL_TIM_OC_DisableFast(TIM1, LL_TIM_CHANNEL_CH1);
  LL_TIM_SetTriggerOutput(TIM1, LL_TIM_TRGO_RESET);
  LL_TIM_DisableMasterSlaveMode(TIM1);
  TIM_BDTRInitStruct.OSSRState = LL_TIM_OSSR_DISABLE;
  TIM_BDTRInitStruct.OSSIState = LL_TIM_OSSI_DISABLE;
  TIM_BDTRInitStruct.LockLevel = LL_TIM_LOCKLEVEL_OFF;
  TIM_BDTRInitStruct.DeadTime = 0;
  TIM_BDTRInitStruct.BreakState = LL_TIM_BREAK_DISABLE;
  TIM_BDTRInitStruct.BreakPolarity = LL_TIM_BREAK_POLARITY_HIGH;
  TIM_BDTRInitStruct.AutomaticOutput = LL_TIM_AUTOMATICOUTPUT_DISABLE;
  LL_TIM_BDTR_Init(TIM1, &TIM_BDTRInitStruct);
  LL_AHB1_GRP1_EnableClock(LL_AHB1_GRP1_PERIPH_GPIOA);
  /**TIM1 GPIO Configuration
  PA8   ------> TIM1_CH1
  */
  GPIO_InitStruct.Pin = PWM_CON_1_Pin;
  GPIO_InitStruct.Mode = LL_GPIO_MODE_ALTERNATE;
  GPIO_InitStruct.Speed = LL_GPIO_SPEED_FREQ_LOW;
  GPIO_InitStruct.OutputType = LL_GPIO_OUTPUT_PUSHPULL;
  GPIO_InitStruct.Pull = LL_GPIO_PULL_NO;
  GPIO_InitStruct.Alternate = LL_GPIO_AF_1;
  LL_GPIO_Init(PWM_CON_1_GPIO_Port, &GPIO_InitStruct);

  LL_TIM_CC_EnableChannel(TIM1, LL_TIM_CHANNEL_CH1);
  LL_TIM_EnableAllOutputs(TIM1);
  LL_TIM_EnableCounter(TIM1);
}

static void MX_TIM2_Init(void)
{

  LL_TIM_InitTypeDef TIM_InitStruct = {0};
  LL_TIM_OC_InitTypeDef TIM_OC_InitStruct = {0};

  LL_GPIO_InitTypeDef GPIO_InitStruct = {0};

  /* Peripheral clock enable */
  LL_APB1_GRP1_EnableClock(LL_APB1_GRP1_PERIPH_TIM2);

  TIM_InitStruct.Prescaler = 83;
  TIM_InitStruct.CounterMode = LL_TIM_COUNTERMODE_UP;
  TIM_InitStruct.Autoreload = 999;
  TIM_InitStruct.ClockDivision = LL_TIM_CLOCKDIVISION_DIV1;
  LL_TIM_Init(TIM2, &TIM_InitStruct);
  LL_TIM_DisableARRPreload(TIM2);
  LL_TIM_OC_EnablePreload(TIM2, LL_TIM_CHANNEL_CH3);
  TIM_OC_InitStruct.OCMode = LL_TIM_OCMODE_PWM1;
  TIM_OC_InitStruct.OCState = LL_TIM_OCSTATE_DISABLE;
  TIM_OC_InitStruct.OCNState = LL_TIM_OCSTATE_DISABLE;
  TIM_OC_InitStruct.CompareValue = 0;
  TIM_OC_InitStruct.OCPolarity = LL_TIM_OCPOLARITY_HIGH;
  LL_TIM_OC_Init(TIM2, LL_TIM_CHANNEL_CH3, &TIM_OC_InitStruct);
  LL_TIM_OC_DisableFast(TIM2, LL_TIM_CHANNEL_CH3);
  LL_TIM_SetTriggerOutput(TIM2, LL_TIM_TRGO_RESET);
  LL_TIM_DisableMasterSlaveMode(TIM2);
  LL_AHB1_GRP1_EnableClock(LL_AHB1_GRP1_PERIPH_GPIOB);
  /**TIM2 GPIO Configuration
  PB10   ------> TIM2_CH3
  */
  GPIO_InitStruct.Pin = PWM_CON_2_Pin;
  GPIO_InitStruct.Mode = LL_GPIO_MODE_ALTERNATE;
  GPIO_InitStruct.Speed = LL_GPIO_SPEED_FREQ_LOW;
  GPIO_InitStruct.OutputType = LL_GPIO_OUTPUT_PUSHPULL;
  GPIO_InitStruct.Pull = LL_GPIO_PULL_NO;
  GPIO_InitStruct.Alternate = LL_GPIO_AF_1;
  LL_GPIO_Init(PWM_CON_2_GPIO_Port, &GPIO_InitStruct);
  LL_TIM_CC_EnableChannel(TIM2, LL_TIM_CHANNEL_CH3);
  LL_TIM_EnableCounter(TIM2);
}

static void MX_TIM3_Init(void)
{

  LL_TIM_InitTypeDef TIM_InitStruct = {0};
  LL_TIM_OC_InitTypeDef TIM_OC_InitStruct = {0};

  LL_GPIO_InitTypeDef GPIO_InitStruct = {0};

  /* Peripheral clock enable */
  LL_APB1_GRP1_EnableClock(LL_APB1_GRP1_PERIPH_TIM3);

  TIM_InitStruct.Prescaler = 83;
  TIM_InitStruct.CounterMode = LL_TIM_COUNTERMODE_UP;
  TIM_InitStruct.Autoreload = 999;
  TIM_InitStruct.ClockDivision = LL_TIM_CLOCKDIVISION_DIV1;
  LL_TIM_Init(TIM3, &TIM_InitStruct);
  LL_TIM_DisableARRPreload(TIM3);
  LL_TIM_OC_EnablePreload(TIM3, LL_TIM_CHANNEL_CH1);
  TIM_OC_InitStruct.OCMode = LL_TIM_OCMODE_PWM1;
  TIM_OC_InitStruct.OCState = LL_TIM_OCSTATE_DISABLE;
  TIM_OC_InitStruct.OCNState = LL_TIM_OCSTATE_DISABLE;
  TIM_OC_InitStruct.CompareValue = 0;
  TIM_OC_InitStruct.OCPolarity = LL_TIM_OCPOLARITY_HIGH;
  LL_TIM_OC_Init(TIM3, LL_TIM_CHANNEL_CH1, &TIM_OC_InitStruct);
  LL_TIM_OC_DisableFast(TIM3, LL_TIM_CHANNEL_CH1);
  LL_TIM_OC_EnablePreload(TIM3, LL_TIM_CHANNEL_CH2);
  LL_TIM_OC_Init(TIM3, LL_TIM_CHANNEL_CH2, &TIM_OC_InitStruct);
  LL_TIM_OC_DisableFast(TIM3, LL_TIM_CHANNEL_CH2);
  LL_TIM_OC_EnablePreload(TIM3, LL_TIM_CHANNEL_CH3);
  LL_TIM_OC_Init(TIM3, LL_TIM_CHANNEL_CH3, &TIM_OC_InitStruct);
  LL_TIM_OC_DisableFast(TIM3, LL_TIM_CHANNEL_CH3);
  LL_TIM_SetTriggerOutput(TIM3, LL_TIM_TRGO_RESET);
  LL_TIM_DisableMasterSlaveMode(TIM3);
  LL_AHB1_GRP1_EnableClock(LL_AHB1_GRP1_PERIPH_GPIOC);
  /**TIM3 GPIO Configuration
  PC6   ------> TIM3_CH1
  PC7   ------> TIM3_CH2
  PC8   ------> TIM3_CH3
  */
  GPIO_InitStruct.Pin = RGB_Blue_Pin|RGB_Green_Pin|RGB_Red_Pin;
  GPIO_InitStruct.Mode = LL_GPIO_MODE_ALTERNATE;
  GPIO_InitStruct.Speed = LL_GPIO_SPEED_FREQ_LOW;
  GPIO_InitStruct.OutputType = LL_GPIO_OUTPUT_PUSHPULL;
  GPIO_InitStruct.Pull = LL_GPIO_PULL_NO;
  GPIO_InitStruct.Alternate = LL_GPIO_AF_2;
  LL_GPIO_Init(GPIOC, &GPIO_InitStruct);
  LL_TIM_CC_EnableChannel(TIM3, LL_TIM_CHANNEL_CH1);
  LL_TIM_CC_EnableChannel(TIM3, LL_TIM_CHANNEL_CH2);
  LL_TIM_CC_EnableChannel(TIM3, LL_TIM_CHANNEL_CH3);
  LL_TIM_EnableCounter(TIM3);
}

static void MX_TIM4_Init(void)
{

  LL_TIM_InitTypeDef TIM_InitStruct = {0};
  LL_TIM_OC_InitTypeDef TIM_OC_InitStruct = {0};

  LL_GPIO_InitTypeDef GPIO_InitStruct = {0};

  /* Peripheral clock enable */
  LL_APB1_GRP1_EnableClock(LL_APB1_GRP1_PERIPH_TIM4);

  TIM_InitStruct.Prescaler = 83;
  TIM_InitStruct.CounterMode = LL_TIM_COUNTERMODE_UP;
  TIM_InitStruct.Autoreload = 999;
  TIM_InitStruct.ClockDivision = LL_TIM_CLOCKDIVISION_DIV1;
  LL_TIM_Init(TIM4, &TIM_InitStruct);
  LL_TIM_DisableARRPreload(TIM4);
  LL_TIM_OC_EnablePreload(TIM4, LL_TIM_CHANNEL_CH3);
  TIM_OC_InitStruct.OCMode = LL_TIM_OCMODE_PWM1;
  TIM_OC_InitStruct.OCState = LL_TIM_OCSTATE_DISABLE;
  TIM_OC_InitStruct.OCNState = LL_TIM_OCSTATE_DISABLE;
  TIM_OC_InitStruct.CompareValue = 0;
  TIM_OC_InitStruct.OCPolarity = LL_TIM_OCPOLARITY_HIGH;
  LL_TIM_OC_Init(TIM4, LL_TIM_CHANNEL_CH3, &TIM_OC_InitStruct);
  LL_TIM_OC_DisableFast(TIM4, LL_TIM_CHANNEL_CH3);
  LL_TIM_OC_EnablePreload(TIM4, LL_TIM_CHANNEL_CH4);
  LL_TIM_OC_Init(TIM4, LL_TIM_CHANNEL_CH4, &TIM_OC_InitStruct);
  LL_TIM_OC_DisableFast(TIM4, LL_TIM_CHANNEL_CH4);
  LL_TIM_SetTriggerOutput(TIM4, LL_TIM_TRGO_RESET);
  LL_TIM_DisableMasterSlaveMode(TIM4);
  LL_AHB1_GRP1_EnableClock(LL_AHB1_GRP1_PERIPH_GPIOB);
  /**TIM4 GPIO Configuration
  PB8   ------> TIM4_CH3
  PB9   ------> TIM4_CH4
  */
  GPIO_InitStruct.Pin = PWM_CON_3_Pin|PWM_CON_4_Pin;
  GPIO_InitStruct.Mode = LL_GPIO_MODE_ALTERNATE;
  GPIO_InitStruct.Speed = LL_GPIO_SPEED_FREQ_LOW;
  GPIO_InitStruct.OutputType = LL_GPIO_OUTPUT_PUSHPULL;
  GPIO_InitStruct.Pull = LL_GPIO_PULL_NO;
  GPIO_InitStruct.Alternate = LL_GPIO_AF_2;
  LL_GPIO_Init(GPIOB, &GPIO_InitStruct);
  LL_TIM_CC_EnableChannel(TIM4, LL_TIM_CHANNEL_CH3);
  LL_TIM_CC_EnableChannel(TIM4, LL_TIM_CHANNEL_CH4);
  LL_TIM_EnableCounter(TIM4);
}

static void MX_TIM8_Init(void)
{

  LL_TIM_InitTypeDef TIM_InitStruct = {0};
  LL_TIM_OC_InitTypeDef TIM_OC_InitStruct = {0};
  LL_TIM_BDTR_InitTypeDef TIM_BDTRInitStruct = {0};

  LL_GPIO_InitTypeDef GPIO_InitStruct = {0};

  /* Peripheral clock enable */
  LL_APB2_GRP1_EnableClock(LL_APB2_GRP1_PERIPH_TIM8);

  TIM_InitStruct.Prescaler = 83;
  TIM_InitStruct.CounterMode = LL_TIM_COUNTERMODE_UP;
  TIM_InitStruct.Autoreload = 999;
  TIM_InitStruct.ClockDivision = LL_TIM_CLOCKDIVISION_DIV1;
  TIM_InitStruct.RepetitionCounter = 0;
  LL_TIM_Init(TIM8, &TIM_InitStruct);
  LL_TIM_DisableARRPreload(TIM8);
  LL_TIM_OC_EnablePreload(TIM8, LL_TIM_CHANNEL_CH4);
  TIM_OC_InitStruct.OCMode = LL_TIM_OCMODE_PWM1;
  TIM_OC_InitStruct.OCState = LL_TIM_OCSTATE_DISABLE;
  TIM_OC_InitStruct.OCNState = LL_TIM_OCSTATE_DISABLE;
  TIM_OC_InitStruct.CompareValue = 0;
  TIM_OC_InitStruct.OCPolarity = LL_TIM_OCPOLARITY_HIGH;
  TIM_OC_InitStruct.OCIdleState = LL_TIM_OCIDLESTATE_LOW;
  TIM_OC_InitStruct.OCNIdleState = LL_TIM_OCIDLESTATE_LOW;
  LL_TIM_OC_Init(TIM8, LL_TIM_CHANNEL_CH4, &TIM_OC_InitStruct);
  LL_TIM_OC_DisableFast(TIM8, LL_TIM_CHANNEL_CH4);
  LL_TIM_SetTriggerOutput(TIM8, LL_TIM_TRGO_RESET);
  LL_TIM_DisableMasterSlaveMode(TIM8);
  TIM_BDTRInitStruct.OSSRState = LL_TIM_OSSR_DISABLE;
  TIM_BDTRInitStruct.OSSIState = LL_TIM_OSSI_DISABLE;
  TIM_BDTRInitStruct.LockLevel = LL_TIM_LOCKLEVEL_OFF;
  TIM_BDTRInitStruct.DeadTime = 0;
  TIM_BDTRInitStruct.BreakState = LL_TIM_BREAK_DISABLE;
  TIM_BDTRInitStruct.BreakPolarity = LL_TIM_BREAK_POLARITY_HIGH;
  TIM_BDTRInitStruct.AutomaticOutput = LL_TIM_AUTOMATICOUTPUT_DISABLE;
  LL_TIM_BDTR_Init(TIM8, &TIM_BDTRInitStruct);
  LL_AHB1_GRP1_EnableClock(LL_AHB1_GRP1_PERIPH_GPIOC);
  /**TIM8 GPIO Configuration
  PC9   ------> TIM8_CH4
  */
  GPIO_InitStruct.Pin = Buzzer_Pin;
  GPIO_InitStruct.Mode = LL_GPIO_MODE_ALTERNATE;
  GPIO_InitStruct.Speed = LL_GPIO_SPEED_FREQ_LOW;
  GPIO_InitStruct.OutputType = LL_GPIO_OUTPUT_PUSHPULL;
  GPIO_InitStruct.Pull = LL_GPIO_PULL_NO;
  GPIO_InitStruct.Alternate = LL_GPIO_AF_3;
  LL_GPIO_Init(Buzzer_GPIO_Port, &GPIO_InitStruct);
  LL_TIM_CC_EnableChannel(TIM8, LL_TIM_CHANNEL_CH4);
  LL_TIM_EnableAllOutputs(TIM8);
  LL_TIM_EnableCounter(TIM8);
}

static void MX_TIM13_Init(void)
{

  LL_TIM_InitTypeDef TIM_InitStruct = {0};
  LL_TIM_OC_InitTypeDef TIM_OC_InitStruct = {0};

  /* Peripheral clock enable */
  LL_APB1_GRP1_EnableClock(LL_APB1_GRP1_PERIPH_TIM13);

  /* TIM13 interrupt Init */
  NVIC_SetPriority(TIM8_UP_TIM13_IRQn, NVIC_EncodePriority(NVIC_GetPriorityGrouping(),0, 0));
  NVIC_EnableIRQ(TIM8_UP_TIM13_IRQn);

  TIM_InitStruct.Prescaler = 83;
  TIM_InitStruct.CounterMode = LL_TIM_COUNTERMODE_UP;
  TIM_InitStruct.Autoreload = 999;
  TIM_InitStruct.ClockDivision = LL_TIM_CLOCKDIVISION_DIV1;
  LL_TIM_Init(TIM13, &TIM_InitStruct);
  LL_TIM_DisableARRPreload(TIM13);
  TIM_OC_InitStruct.OCMode = LL_TIM_OCMODE_FROZEN;
  TIM_OC_InitStruct.OCState = LL_TIM_OCSTATE_DISABLE;
  TIM_OC_InitStruct.OCNState = LL_TIM_OCSTATE_DISABLE;
  TIM_OC_InitStruct.CompareValue = 500;
  TIM_OC_InitStruct.OCPolarity = LL_TIM_OCPOLARITY_HIGH;
  LL_TIM_OC_Init(TIM13, LL_TIM_CHANNEL_CH1, &TIM_OC_InitStruct);
  LL_TIM_OC_DisableFast(TIM13, LL_TIM_CHANNEL_CH1);
  LL_TIM_ClearFlag_UPDATE(TIM13);
  LL_TIM_EnableIT_UPDATE(TIM13);
  LL_TIM_EnableCounter(TIM13);

}

static void MX_USART1_UART_Init(void)
{

  LL_USART_InitTypeDef USART_InitStruct = {0};

  LL_GPIO_InitTypeDef GPIO_InitStruct = {0};

  /* Peripheral clock enable */
  LL_APB2_GRP1_EnableClock(LL_APB2_GRP1_PERIPH_USART1);

  LL_AHB1_GRP1_EnableClock(LL_AHB1_GRP1_PERIPH_GPIOA);
  /**USART1 GPIO Configuration
  PA9   ------> USART1_TX
  PA10   ------> USART1_RX
  */
  GPIO_InitStruct.Pin = LL_GPIO_PIN_9|LL_GPIO_PIN_10;
  GPIO_InitStruct.Mode = LL_GPIO_MODE_ALTERNATE;
  GPIO_InitStruct.Speed = LL_GPIO_SPEED_FREQ_VERY_HIGH;
  GPIO_InitStruct.OutputType = LL_GPIO_OUTPUT_PUSHPULL;
  GPIO_InitStruct.Pull = LL_GPIO_PULL_NO;
  GPIO_InitStruct.Alternate = LL_GPIO_AF_7;
  LL_GPIO_Init(GPIOA, &GPIO_InitStruct);

  /* USART1 DMA Init */

  /* USART1_RX Init */
  LL_DMA_SetChannelSelection(DMA2, LL_DMA_STREAM_2, LL_DMA_CHANNEL_4);

  LL_DMA_SetDataTransferDirection(DMA2, LL_DMA_STREAM_2, LL_DMA_DIRECTION_PERIPH_TO_MEMORY);

  LL_DMA_SetStreamPriorityLevel(DMA2, LL_DMA_STREAM_2, LL_DMA_PRIORITY_LOW);

  LL_DMA_SetMode(DMA2, LL_DMA_STREAM_2, LL_DMA_MODE_CIRCULAR);

  LL_DMA_SetPeriphIncMode(DMA2, LL_DMA_STREAM_2, LL_DMA_PERIPH_NOINCREMENT);

  LL_DMA_SetMemoryIncMode(DMA2, LL_DMA_STREAM_2, LL_DMA_MEMORY_INCREMENT);

  LL_DMA_SetPeriphSize(DMA2, LL_DMA_STREAM_2, LL_DMA_PDATAALIGN_BYTE);

  LL_DMA_SetMemorySize(DMA2, LL_DMA_STREAM_2, LL_DMA_MDATAALIGN_BYTE);

  LL_DMA_DisableFifoMode(DMA2, LL_DMA_STREAM_2);

  /* USART1_TX Init */
  LL_DMA_SetChannelSelection(DMA2, LL_DMA_STREAM_7, LL_DMA_CHANNEL_4);

  LL_DMA_SetDataTransferDirection(DMA2, LL_DMA_STREAM_7, LL_DMA_DIRECTION_MEMORY_TO_PERIPH);

  LL_DMA_SetStreamPriorityLevel(DMA2, LL_DMA_STREAM_7, LL_DMA_PRIORITY_LOW);

  LL_DMA_SetMode(DMA2, LL_DMA_STREAM_7, LL_DMA_MODE_NORMAL);

  LL_DMA_SetPeriphIncMode(DMA2, LL_DMA_STREAM_7, LL_DMA_PERIPH_NOINCREMENT);

  LL_DMA_SetMemoryIncMode(DMA2, LL_DMA_STREAM_7, LL_DMA_MEMORY_INCREMENT);

  LL_DMA_SetPeriphSize(DMA2, LL_DMA_STREAM_7, LL_DMA_PDATAALIGN_BYTE);

  LL_DMA_SetMemorySize(DMA2, LL_DMA_STREAM_7, LL_DMA_MDATAALIGN_BYTE);

  LL_DMA_DisableFifoMode(DMA2, LL_DMA_STREAM_7);

  /* USER CODE BEGIN USART1_Init 1 */
  LL_GPIO_SetPinPull(GPIOA, LL_GPIO_PIN_10, LL_GPIO_PULL_UP); /* RX pull-up */
  /* USER CODE END USART1_Init 1 */
  USART_InitStruct.BaudRate = 115200;
  USART_InitStruct.DataWidth = LL_USART_DATAWIDTH_8B;
  USART_InitStruct.StopBits = LL_USART_STOPBITS_1;
  USART_InitStruct.Parity = LL_USART_PARITY_NONE;
  USART_InitStruct.TransferDirection = LL_USART_DIRECTION_TX_RX;
  USART_InitStruct.HardwareFlowControl = LL_USART_HWCONTROL_NONE;
  USART_InitStruct.OverSampling = LL_USART_OVERSAMPLING_16;
  LL_USART_Init(USART1, &USART_InitStruct);
  LL_USART_ConfigAsyncMode(USART1);
  LL_USART_Enable(USART1);

  LL_USART_EnableDMAReq_RX(USART1);
  LL_USART_EnableDMAReq_TX(USART1);
}

static void MX_USART2_UART_Init(void)
{

  LL_USART_InitTypeDef USART_InitStruct = {0};

  LL_GPIO_InitTypeDef GPIO_InitStruct = {0};

  /* Peripheral clock enable */
  LL_APB1_GRP1_EnableClock(LL_APB1_GRP1_PERIPH_USART2);

  LL_AHB1_GRP1_EnableClock(LL_AHB1_GRP1_PERIPH_GPIOA);
  /**USART2 GPIO Configuration
  PA2   ------> USART2_TX
  PA3   ------> USART2_RX
  */
  GPIO_InitStruct.Pin = LL_GPIO_PIN_2|LL_GPIO_PIN_3;
  GPIO_InitStruct.Mode = LL_GPIO_MODE_ALTERNATE;
  GPIO_InitStruct.Speed = LL_GPIO_SPEED_FREQ_VERY_HIGH;
  GPIO_InitStruct.OutputType = LL_GPIO_OUTPUT_PUSHPULL;
  GPIO_InitStruct.Pull = LL_GPIO_PULL_NO;
  GPIO_InitStruct.Alternate = LL_GPIO_AF_7;
  LL_GPIO_Init(GPIOA, &GPIO_InitStruct);

  /* USART2 DMA Init */

  /* USART2_RX Init */
  LL_DMA_SetChannelSelection(DMA1, LL_DMA_STREAM_5, LL_DMA_CHANNEL_4);

  LL_DMA_SetDataTransferDirection(DMA1, LL_DMA_STREAM_5, LL_DMA_DIRECTION_PERIPH_TO_MEMORY);

  LL_DMA_SetStreamPriorityLevel(DMA1, LL_DMA_STREAM_5, LL_DMA_PRIORITY_LOW);

  LL_DMA_SetMode(DMA1, LL_DMA_STREAM_5, LL_DMA_MODE_CIRCULAR);

  LL_DMA_SetPeriphIncMode(DMA1, LL_DMA_STREAM_5, LL_DMA_PERIPH_NOINCREMENT);

  LL_DMA_SetMemoryIncMode(DMA1, LL_DMA_STREAM_5, LL_DMA_MEMORY_INCREMENT);

  LL_DMA_SetPeriphSize(DMA1, LL_DMA_STREAM_5, LL_DMA_PDATAALIGN_BYTE);

  LL_DMA_SetMemorySize(DMA1, LL_DMA_STREAM_5, LL_DMA_MDATAALIGN_BYTE);

  LL_DMA_DisableFifoMode(DMA1, LL_DMA_STREAM_5);

  /* USART2_TX Init */
  LL_DMA_SetChannelSelection(DMA1, LL_DMA_STREAM_6, LL_DMA_CHANNEL_4);

  LL_DMA_SetDataTransferDirection(DMA1, LL_DMA_STREAM_6, LL_DMA_DIRECTION_MEMORY_TO_PERIPH);

  LL_DMA_SetStreamPriorityLevel(DMA1, LL_DMA_STREAM_6, LL_DMA_PRIORITY_LOW);

  LL_DMA_SetMode(DMA1, LL_DMA_STREAM_6, LL_DMA_MODE_NORMAL);

  LL_DMA_SetPeriphIncMode(DMA1, LL_DMA_STREAM_6, LL_DMA_PERIPH_NOINCREMENT);

  LL_DMA_SetMemoryIncMode(DMA1, LL_DMA_STREAM_6, LL_DMA_MEMORY_INCREMENT);

  LL_DMA_SetPeriphSize(DMA1, LL_DMA_STREAM_6, LL_DMA_PDATAALIGN_BYTE);

  LL_DMA_SetMemorySize(DMA1, LL_DMA_STREAM_6, LL_DMA_MDATAALIGN_BYTE);

  LL_DMA_DisableFifoMode(DMA1, LL_DMA_STREAM_6);

  /* USER CODE BEGIN USART2_Init 1 */
  LL_GPIO_SetPinPull(GPIOA, LL_GPIO_PIN_3, LL_GPIO_PULL_UP); /* RX pull-up */
  /* USER CODE END USART2_Init 1 */
  USART_InitStruct.BaudRate = 115200;
  USART_InitStruct.DataWidth = LL_USART_DATAWIDTH_8B;
  USART_InitStruct.StopBits = LL_USART_STOPBITS_1;
  USART_InitStruct.Parity = LL_USART_PARITY_NONE;
  USART_InitStruct.TransferDirection = LL_USART_DIRECTION_TX_RX;
  USART_InitStruct.HardwareFlowControl = LL_USART_HWCONTROL_NONE;
  USART_InitStruct.OverSampling = LL_USART_OVERSAMPLING_16;
  LL_USART_Init(USART2, &USART_InitStruct);
  LL_USART_ConfigAsyncMode(USART2);
  LL_USART_Enable(USART2);

  LL_USART_EnableDMAReq_RX(USART2);
  LL_USART_EnableDMAReq_TX(USART2);

}

static void MX_DMA_Init(void)
{

  /* Init with LL driver */
  /* DMA controller clock enable */
  LL_AHB1_GRP1_EnableClock(LL_AHB1_GRP1_PERIPH_DMA2);
  LL_AHB1_GRP1_EnableClock(LL_AHB1_GRP1_PERIPH_DMA1);

  /* DMA interrupt init */
  /* DMA1_Stream0_IRQn interrupt configuration */
  NVIC_SetPriority(DMA1_Stream0_IRQn, NVIC_EncodePriority(NVIC_GetPriorityGrouping(),0, 0));
  NVIC_EnableIRQ(DMA1_Stream0_IRQn);
  /* DMA1_Stream1_IRQn interrupt configuration */
  NVIC_SetPriority(DMA1_Stream1_IRQn, NVIC_EncodePriority(NVIC_GetPriorityGrouping(),0, 0));
  NVIC_EnableIRQ(DMA1_Stream1_IRQn);
  /* DMA1_Stream5_IRQn interrupt configuration */
  NVIC_SetPriority(DMA1_Stream5_IRQn, NVIC_EncodePriority(NVIC_GetPriorityGrouping(),0, 0));
  NVIC_EnableIRQ(DMA1_Stream5_IRQn);
  /* DMA1_Stream6_IRQn interrupt configuration */
  NVIC_SetPriority(DMA1_Stream6_IRQn, NVIC_EncodePriority(NVIC_GetPriorityGrouping(),0, 0));
  NVIC_EnableIRQ(DMA1_Stream6_IRQn);
  /* DMA2_Stream0_IRQn interrupt configuration */
  NVIC_SetPriority(DMA2_Stream0_IRQn, NVIC_EncodePriority(NVIC_GetPriorityGrouping(),0, 0));
  NVIC_EnableIRQ(DMA2_Stream0_IRQn);
  /* DMA2_Stream2_IRQn interrupt configuration */
  NVIC_SetPriority(DMA2_Stream2_IRQn, NVIC_EncodePriority(NVIC_GetPriorityGrouping(),0, 0));
  NVIC_EnableIRQ(DMA2_Stream2_IRQn);
  /* DMA2_Stream3_IRQn interrupt configuration */
  NVIC_SetPriority(DMA2_Stream3_IRQn, NVIC_EncodePriority(NVIC_GetPriorityGrouping(),0, 0));
  NVIC_EnableIRQ(DMA2_Stream3_IRQn);
  /* DMA2_Stream4_IRQn interrupt configuration */
  NVIC_SetPriority(DMA2_Stream4_IRQn, NVIC_EncodePriority(NVIC_GetPriorityGrouping(),0, 0));
  NVIC_EnableIRQ(DMA2_Stream4_IRQn);
  /* DMA2_Stream7_IRQn interrupt configuration */
  NVIC_SetPriority(DMA2_Stream7_IRQn, NVIC_EncodePriority(NVIC_GetPriorityGrouping(),0, 0));
  NVIC_EnableIRQ(DMA2_Stream7_IRQn);

}

static void MX_GPIO_Init(void)
{
  LL_EXTI_InitTypeDef EXTI_InitStruct = {0};
  LL_GPIO_InitTypeDef GPIO_InitStruct = {0};
  /* USER CODE BEGIN MX_GPIO_Init_1 */
  LL_GPIO_SetOutputPin(GPIOC, SPI1_CS2_Pin | FLASH_Hold_Pin);
  /* USER CODE END MX_GPIO_Init_1 */

  /* GPIO Ports Clock Enable */
  LL_AHB1_GRP1_EnableClock(LL_AHB1_GRP1_PERIPH_GPIOC);
  LL_AHB1_GRP1_EnableClock(LL_AHB1_GRP1_PERIPH_GPIOH);
  LL_AHB1_GRP1_EnableClock(LL_AHB1_GRP1_PERIPH_GPIOA);
  LL_AHB1_GRP1_EnableClock(LL_AHB1_GRP1_PERIPH_GPIOB);

  /**/
  LL_GPIO_ResetOutputPin(GPIOC, FLASH_Hold_Pin|CON_1_Pin|CON_2_Pin|CON_3_Pin
                          |CON_4_Pin|ESP32_Write_Pin|SPI1_CS2_Pin);

  /**/
  LL_GPIO_ResetOutputPin(SPI1_CS1_GPIO_Port, SPI1_CS1_Pin);

  /**/
  LL_GPIO_ResetOutputPin(GPIOB, ESP_GPIO01_Pin|CON_5_Pin|ESP32_Reset_Pin|LED1_Pin
                          |LED2_Pin);

  /**/
  GPIO_InitStruct.Pin = FLASH_Hold_Pin|CON_1_Pin|CON_2_Pin|CON_3_Pin
                          |CON_4_Pin|ESP32_Write_Pin|SPI1_CS2_Pin;
  GPIO_InitStruct.Mode = LL_GPIO_MODE_OUTPUT;
  GPIO_InitStruct.Speed = LL_GPIO_SPEED_FREQ_LOW;
  GPIO_InitStruct.OutputType = LL_GPIO_OUTPUT_PUSHPULL;
  GPIO_InitStruct.Pull = LL_GPIO_PULL_NO;
  LL_GPIO_Init(GPIOC, &GPIO_InitStruct);

  /**/
  GPIO_InitStruct.Pin = SPI1_CS1_Pin;
  GPIO_InitStruct.Mode = LL_GPIO_MODE_OUTPUT;
  GPIO_InitStruct.Speed = LL_GPIO_SPEED_FREQ_LOW;
  GPIO_InitStruct.OutputType = LL_GPIO_OUTPUT_PUSHPULL;
  GPIO_InitStruct.Pull = LL_GPIO_PULL_NO;
  LL_GPIO_Init(SPI1_CS1_GPIO_Port, &GPIO_InitStruct);

  /**/
  GPIO_InitStruct.Pin = ESP32_Status_Pin;
  GPIO_InitStruct.Mode = LL_GPIO_MODE_INPUT;
  GPIO_InitStruct.Pull = LL_GPIO_PULL_NO;
  LL_GPIO_Init(ESP32_Status_GPIO_Port, &GPIO_InitStruct);

  /**/
  GPIO_InitStruct.Pin = ESP_GPIO01_Pin|CON_5_Pin|ESP32_Reset_Pin|LED1_Pin
                          |LED2_Pin;
  GPIO_InitStruct.Mode = LL_GPIO_MODE_OUTPUT;
  GPIO_InitStruct.Speed = LL_GPIO_SPEED_FREQ_LOW;
  GPIO_InitStruct.OutputType = LL_GPIO_OUTPUT_PUSHPULL;
  GPIO_InitStruct.Pull = LL_GPIO_PULL_NO;
  LL_GPIO_Init(GPIOB, &GPIO_InitStruct);

  /**/
  LL_SYSCFG_SetEXTISource(LL_SYSCFG_EXTI_PORTB, LL_SYSCFG_EXTI_LINE0);

  /**/
  LL_SYSCFG_SetEXTISource(LL_SYSCFG_EXTI_PORTB, LL_SYSCFG_EXTI_LINE1);

  /**/
  LL_SYSCFG_SetEXTISource(LL_SYSCFG_EXTI_PORTB, LL_SYSCFG_EXTI_LINE5);

  /**/
  EXTI_InitStruct.Line_0_31 = LL_EXTI_LINE_0;
  EXTI_InitStruct.LineCommand = ENABLE;
  EXTI_InitStruct.Mode = LL_EXTI_MODE_IT;
  EXTI_InitStruct.Trigger = LL_EXTI_TRIGGER_FALLING;
  LL_EXTI_Init(&EXTI_InitStruct);

  NVIC_SetPriority(EXTI0_IRQn, NVIC_EncodePriority(NVIC_GetPriorityGrouping(),0, 0));
  NVIC_EnableIRQ(EXTI0_IRQn);

  /**/
  EXTI_InitStruct.Line_0_31 = LL_EXTI_LINE_1;
  EXTI_InitStruct.LineCommand = ENABLE;
  EXTI_InitStruct.Mode = LL_EXTI_MODE_IT;
  EXTI_InitStruct.Trigger = LL_EXTI_TRIGGER_FALLING;
  LL_EXTI_Init(&EXTI_InitStruct);

  NVIC_SetPriority(EXTI1_IRQn, NVIC_EncodePriority(NVIC_GetPriorityGrouping(),0, 0));
  NVIC_EnableIRQ(EXTI1_IRQn);

  /**/
  EXTI_InitStruct.Line_0_31 = LL_EXTI_LINE_5;
  EXTI_InitStruct.LineCommand = ENABLE;
  EXTI_InitStruct.Mode = LL_EXTI_MODE_IT;
  EXTI_InitStruct.Trigger = LL_EXTI_TRIGGER_FALLING;
  LL_EXTI_Init(&EXTI_InitStruct);

  NVIC_SetPriority(EXTI9_5_IRQn, NVIC_EncodePriority(NVIC_GetPriorityGrouping(),0, 0));
  NVIC_EnableIRQ(EXTI9_5_IRQn);

  /**/
  LL_GPIO_SetPinPull(BTN1_GPIO_Port, BTN1_Pin, LL_GPIO_PULL_UP);

  /**/
  LL_GPIO_SetPinPull(BTN2_GPIO_Port, BTN2_Pin, LL_GPIO_PULL_UP);

  /**/
  LL_GPIO_SetPinPull(MFP_GPIO_Port, MFP_Pin, LL_GPIO_PULL_NO);

  /**/
  LL_GPIO_SetPinMode(BTN1_GPIO_Port, BTN1_Pin, LL_GPIO_MODE_INPUT);

  /**/
  LL_GPIO_SetPinMode(BTN2_GPIO_Port, BTN2_Pin, LL_GPIO_MODE_INPUT);

  /**/
  LL_GPIO_SetPinMode(MFP_GPIO_Port, MFP_Pin, LL_GPIO_MODE_INPUT);

}

void Error_Handler(void)
{
  __disable_irq();
  while (1)
  {
  }
}
